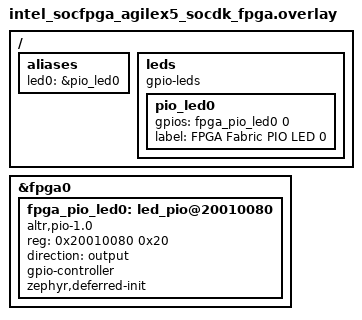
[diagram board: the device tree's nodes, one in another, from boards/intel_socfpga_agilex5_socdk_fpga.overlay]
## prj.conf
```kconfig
CONFIG_GPIO=y

CONFIG_ARM_SIP_SVC_DRIVER=y
CONFIG_ARM_SIP_SVC_SUBSYS=y
CONFIG_ARM_SIP_SVC_SUBSYS_SINGLY_OPEN=y

CONFIG_FPGA_BRIDGE=y
CONFIG_FPGA_BRIDGE_INTEL=y

CONFIG_HEAP_MEM_POOL_SIZE=65536
```

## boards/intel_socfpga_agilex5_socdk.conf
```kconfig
# Copyright (c) 2026, Intel Corporation.
# SPDX-License-Identifier: Apache-2.0

# FPGA PIO support (use with boards/intel_socfpga_agilex5_socdk_fpga.overlay)
CONFIG_FPGA=y
CONFIG_ALTERA_AGILEX_BRIDGE_FPGA=y
CONFIG_GPIO=y

# FPGA-first: uncomment so boot calls fpga_on() when fabric is already configured.
# CONFIG_FPGA_ALTERA_AUTO_BRINGUP=y
```

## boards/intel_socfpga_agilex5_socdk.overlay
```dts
/*
 * Copyright (C) 2026 Intel Corporation
 * SPDX-License-Identifier: Apache-2.0
 */

/* The overlay file should be used to enable any
 * dts nodes required by this application for this
 * board.
 */

&sip_smc {
        status = "okay";
        zephyr,num-clients = <5>;
};
```

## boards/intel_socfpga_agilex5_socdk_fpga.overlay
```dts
/*
 * Copyright (c) 2026, Intel Corporation
 *
 * SPDX-License-Identifier: Apache-2.0
 */

/*
 * Remap led0 to the FPGA PIO LED. Soft-IP is a child of fpga0 so bridge
 * on/off owns deferred init.
 */

/ {
	aliases {
		led0 = &pio_led0;
	};

	leds {
		compatible = "gpio-leds";

		pio_led0: pio_led0 {
			gpios = <&fpga_pio_led0 0 GPIO_ACTIVE_HIGH>;
			label = "FPGA Fabric PIO LED 0";
		};
	};
};

&fpga0 {
	status = "okay";

	fpga_pio_led0: led_pio@20010080 {
		compatible = "altr,pio-1.0";
		reg = <0x20010080 0x20>;
		direction = "output";
		gpio-controller;
		#gpio-cells = <2>;
		status = "okay";
		zephyr,deferred-init;
	};
};
```

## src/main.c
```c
/*
 * Copyright (c) 2016 Intel Corporation
 *
 * SPDX-License-Identifier: Apache-2.0
 */

#include <stdio.h>
#include <zephyr/kernel.h>
#include <zephyr/drivers/gpio.h>

/* 1000 msec = 1 sec */
#define SLEEP_TIME_MS   1000

/* The devicetree node identifier for the "led0" alias. */
#define LED0_NODE DT_ALIAS(led0)

/*
 * A build error on this line means your board is unsupported.
 * See the sample documentation for information on how to fix this.
 */
static const struct gpio_dt_spec led = GPIO_DT_SPEC_GET(LED0_NODE, gpios);

int main(void)
{
	int ret;
	bool led_state = true;

	if (!gpio_is_ready_dt(&led)) {
		printk("gpio_is_ready_dt failed\n");
		return 0;
	}

	ret = gpio_pin_configure_dt(&led, GPIO_OUTPUT_ACTIVE);
	if (ret < 0) {
		printk("gpio_pin_configure_dt failed ret=%d\n", ret);
		return 0;
	}

	while (1) {
		ret = gpio_pin_toggle_dt(&led);
		if (ret < 0) {
			printk("gpio_pin_toggle_dt failed ret=%d\n", ret);
			return 0;
		}
		ret = gpio_pin_get_dt(&led);
		if(ret < 0) {
			printk("gpio_pin_get_dt failed ret=%d\n", ret);
		}
		led_state = !!ret;
		printf("LED state: %s\n", led_state ? "ON" : "OFF");
		k_msleep(SLEEP_TIME_MS);
	}
	return 0;
}
```
